# IWRL6432 register map
File version: 1.0
CPU: CM4 1.0, other endian, MPU, FPU, 3 interrupt priority bits
Registers are 32-bit, read-write, reset 0x0 unless marked. A register's access mark holds for its fields unless they carry their own. Offsets are from the block's base; [hi:lo] are bit positions; {n}, {i} and the like mark numbered series.

## GPADC_CTRL
Base 0x50F7FC00
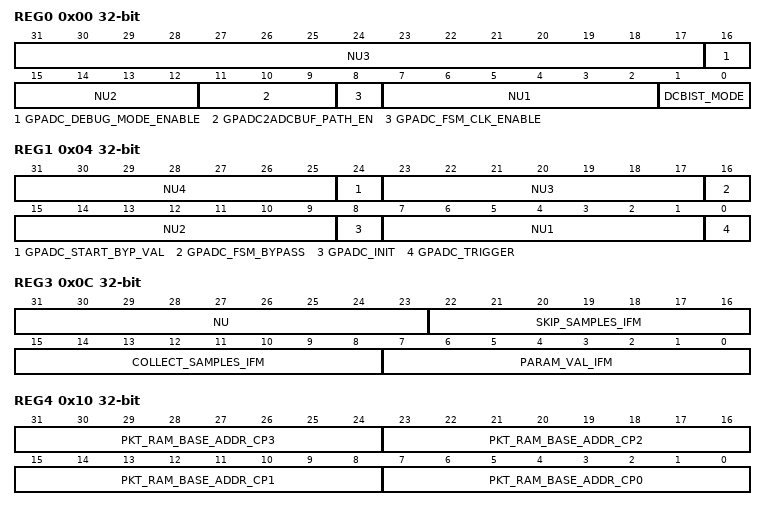
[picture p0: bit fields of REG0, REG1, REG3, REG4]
0x00 REG0 — gpadc modes and enable
  [31:17] NU3 — [31:17] TI reserved
  [16] GPADC_DEBUG_MODE_ENABLE — [16:16] 1:GPADC raw samples will be collected in the Output RAM in IFM mode
  [15:12] NU2 — [15:12] TI reserved
  [11:9] GPADC2ADCBUF_PATH_EN — [11:9] TI reserved
  [8] GPADC_FSM_CLK_ENABLE — [8:8] Enable the clock to gpadc fsm
  [7:2] NU1 — [7:2] TI reserved
  [1:0] DCBIST_MODE — [1:0] 0:Disable,1:IFM Mode enable ,2:CTM mode enable
0x04 REG1 — gpadc start trigger for Inter frame mode
  [8n-1:8n-7] NU{n} (n=1..4) — [{8n-1}:{8n-7}] TI reserved
  [24] GPADC_START_BYP_VAL
  [16] GPADC_FSM_BYPASS — [16:16] 1:Bypass gpadc control .When bypassed start = gpadc_start_byp_val config_val = config_value_ifm param_val = param_val_ifm
  [8] GPADC_INIT — [8:8] Resets the FSM and clears the data RAM
  [0] GPADC_TRIGGER — [0:0] Generates a single cycle pulse to trigger the IFM mode
0x08 REG2 — gpadc config for IFM
  [31:0] CONFIG_VALUE_IFM — [31:0] Configuration value to be passed to analog in IFM mode
0x0C REG3 — gpadc param, skip samples and collect samples for IFM
  [31:23] NU
  [22:16] SKIP_SAMPLES_IFM — [22:16] number of GPADC clocks to skip after trigger . Number of samples to skip = skip_samples_ifm[3:0]x(2skip_samples_ifm[6:4])
  [15:8] COLLECT_SAMPLES_IFM — [15:8] number of GPADC readings to collect
  [7:0] PARAM_VAL_IFM — [7:0] Param value to be passed to analog in IFM mode(after one hot encoding)
0x10 REG4 — Base address for Chirp profile 0 in instruction packet RAM
  [31:24] PKT_RAM_BASE_ADDR_CP3 — [31:24] TI reserved
  [23:16] PKT_RAM_BASE_ADDR_CP2 — [23:16] TI reserved
  [15:8] PKT_RAM_BASE_ADDR_CP1 — [15:8] (End-Address + 1) of instruction-ram in CTM mode
  [7:0] PKT_RAM_BASE_ADDR_CP0 — [7:0] Start Address of instruction-ram in CTM mode
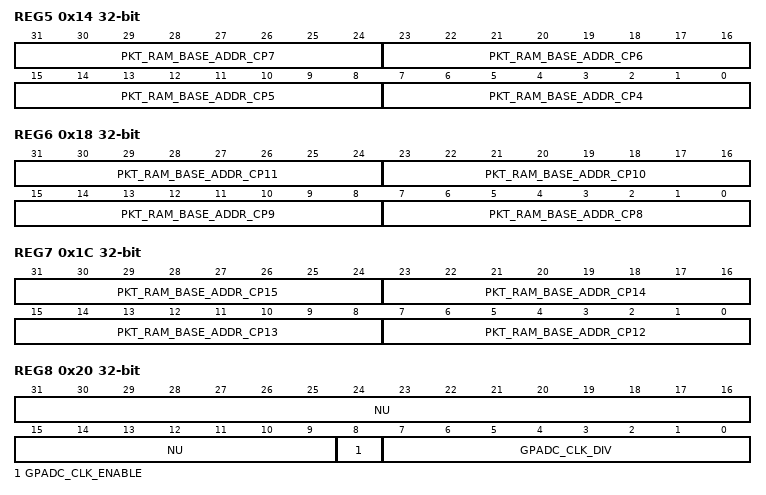
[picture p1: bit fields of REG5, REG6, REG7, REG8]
0x14 REG5 — Base address for Chirp profile 1 in instruction packet RAM
  [8n-25:8n-32] PKT_RAM_BASE_ADDR_CP{n} (n=4..7) — [{8n-25}:{8n-32}] TI reserved
0x18 REG6 — Base address for Chirp profile 2 in instruction packet RAM
  [8n-57:8n-64] PKT_RAM_BASE_ADDR_CP{n} (n=8..11) — [{8n-57}:{8n-64}] TI reserved
0x1C REG7 — Base address for Chirp profile 3 in instruction packet RAM
  [8n-89:8n-96] PKT_RAM_BASE_ADDR_CP{n} (n=12..15) — [{8n-89}:{8n-96}] TI reserved
0x20 REG8
  [31:9] NU
  [8] GPADC_CLK_ENABLE — [8:8] TI reserved
  [7:0] GPADC_CLK_DIV — [7:0] TI reserved
{0x0+4i} REG{i} (i=9..11)
  [31:0] PARAM_NOT_USED_TX_ENA{i-8}_OFF — [31:0] TI reserved
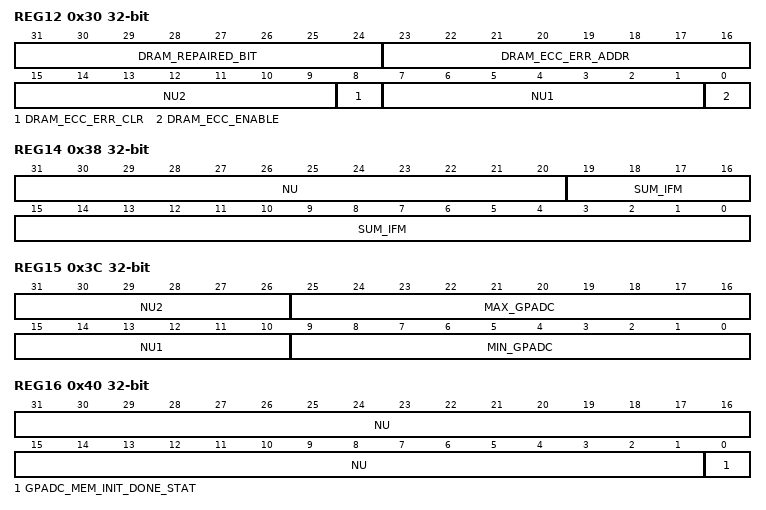
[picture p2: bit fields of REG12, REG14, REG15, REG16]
0x30 REG12
  [31:24] DRAM_REPAIRED_BIT — [31:24] TI reserved
  [23:16] DRAM_ECC_ERR_ADDR — [23:16] TI reserved
  [15:9] NU2 — [15:9] TI reserved
  [8] DRAM_ECC_ERR_CLR — [8:8] TI reserved
  [7:1] NU1 — [7:1] TI reserved
  [0] DRAM_ECC_ENABLE
0x34 REG13
  [31:0] SPARE_WR2 — [31:0] TI reserved
0x38 REG14 — Sum of GP ADC readings
  [31:20] NU — [31:20] TI reserved
  [19:0] SUM_IFM — [19:0] Sum of GP ADC readings
0x3C REG15 — Min and Max of GP ADC readings
  [31:26] NU2 — [31:26] TI reserved
  [25:16] MAX_GPADC — [25:16] Max of GPADC readings
  [15:10] NU1 — [15:10] TI reserved
  [9:0] MIN_GPADC — [9:0] Min of GPADC readings
0x40 REG16
  [31:1] NU — [31:1] TI reserved
  [0] GPADC_MEM_INIT_DONE_STAT — [0:0] Status for Data Mem init done.Used for FW polling .Will read '0' when init process is under progress
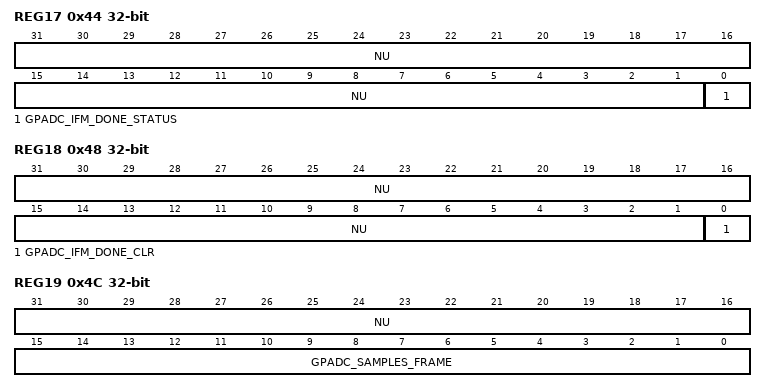
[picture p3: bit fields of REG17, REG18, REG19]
0x44 REG17
  [31:1] NU — [31:1] TI reserved
  [0] GPADC_IFM_DONE_STATUS — [0:0] Test completion status in IFM mode.Used for FW polling
0x48 REG18
  [31:1] NU — [31:1] TI reserved
  [0] GPADC_IFM_DONE_CLR — [0:0] Clear "ifm_done_status"
0x4C REG19
  [31:16] NU — [31:16] TI reserved
  [15:0] GPADC_SAMPLES_FRAME — [15:0] Total number of GPADC samples collected in a frame
0x50 REG20
  [31:0] SPARE_RD1 — [31:0] TI reserved
0x54 REG21
  [31:0] SPARE_RD2 — [31:0] TI reserved
0x58 REG22
  [31:0] SPARE_WR1 — [31:0] TI reserved

## PBIST
Base 0x5C020000
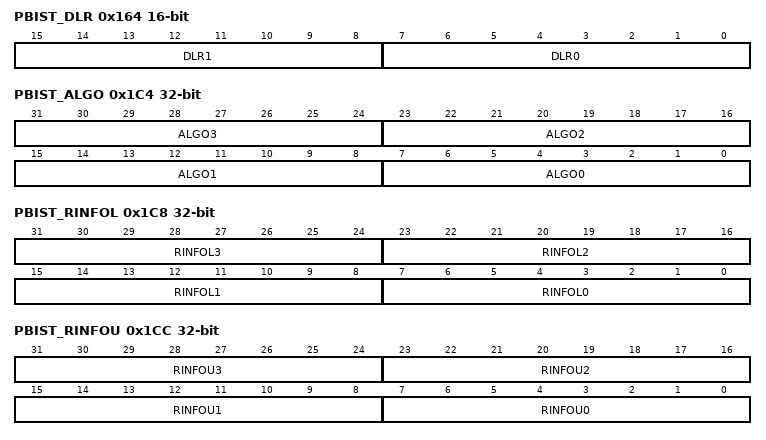
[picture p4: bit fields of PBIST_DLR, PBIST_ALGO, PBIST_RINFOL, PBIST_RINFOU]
0x164 PBIST_DLR 16-bit — Datalogger 0
  [15:8] DLR1 — [15:8] Datalogger Register [8] : Reserevd [9] : Default Testing Mode. When in this mode, ROM-based testing is kicked off. If the intention is to perform go/no-go testing via config, write to both this bit and bit [2] of the Datalogger Register simultaneously [15:10] : Reserevd
  [7:0] DLR0 — [7:0] Datalogger Register [1:0] : Reserved [2] : ROM-based testing mode. Setting this bit to 1 enables the PBIST controller to execute test algorithms that are stored in the PBIST ROM [3] : Do not change this bit from its default value of 1 [4] : Config access mode. Setting this bit allows the host processor to configure the PBIST controller registers [7:5] : Reserved
0x16C PBIST_PC 5-bit — Program Control
  [4:0] PBIST_PC — [4:0] TI Internal Register.Reserved for HW RnD
0x180 PBIST_PACT 1-bit — Pbist Active
  [0] PBIST_PACT — [0:0] Pbist Active/ROM Clock Enable Register [0]: This bit must be set to turn on internal PBIST clocks. Setting this bit asserts an internal signal that is used as the clock gate enable. As long as this bit is 0, any access to PBIST will not go through, and PBIST will remain in an almost zero-power mode. Value 0 = Disable internal PBIST clocks Value 1 = Enable internal PBIST clocks
0x188 PBIST_OVR 4-bit — PBIST Overrides
  [3:0] PBIST_OVR — [3:0] TI Internal Register.Reserved for HW RnD
0x190 PBIST_FSFR0 — Fail status fail - port 0
  [0] PBIST_FSFR0 — [0:0] Fail Status Fail Register- Port 0 This register indicates if a failure occurred during a memory self-test. Value 0 = No failure occurred Value 1 = Indicates a failure
0x194 PBIST_FSFR1 — Fail status fail - port 1
  [0] PBIST_FSFR1 — [0:0] Fail Status Fail Register- Port 1 This register indicates if a failure occurred during a memory self-test. Value 0 = No failure occurred Value 1 = Indicates a failure
0x1C0 PBIST_ROM 2-bit — Rom Mask
  [1:0] PBIST_ROM — [1:0] Rom Mask . This two-bit register sets appropriate ROM access modes for the PBIST controller. Value 0h = No information is used from ROM Value 1h = Only RAM Group information from ROM Vaule 2h = Only Algorithm information from ROM Value 3h = Both Algorithm and RAM information from ROM. This option should be selected for application self-test.
0x1C4 PBIST_ALGO — ROM Algorithm Mask 0
  [8n+7:8n] ALGO{n} (n=0..3) — [{8n+7}:{8n}] This register is used to indicate the algorithm(s) to be used for the memory self-test routine. Each bit corresponds to a specific algorithm. Writing a value 1 to the particular bit, enables the corresponding algorithm. Writing a value 0 to the particular bit, disables the corresponding algorithm.
0x1C8 PBIST_RINFOL — RAM Info Mask Lower 0
  [8n+7:8n] RINFOL{n} (n=0..3) — [{8n+7}:{8n}] This register is to select memory groups to run the algorithms selected in the PBIST_ALGO register. For an algorithmto be executed on a particular memory group, the corresponding bit in this register must be set to 1. The default value of this register is all 1s, which means all the memory groups are selected. Writing a value 0 to the particular bit, disables the corresponding memory group.
0x1CC PBIST_RINFOU — RAM Info Mask Upper 0
  [8n+7:8n] RINFOU{n} (n=0..3) — [{8n+7}:{8n}] This register is to select memory groups to run the algorithms selected in the PBIST_ALGO register. For an algorithmto be executed on a particular memory group, the corresponding bit in this register must be set to 1. The default value of this register is all 1s, which means all the memory groups are selected. Writing a value 0 to the particular bit, disables the corresponding memory group.
